# MDR1206AFI register map
Vendor: Milandr; File version: 2.0
CPU: BM-310S0, little endian
Registers are 32-bit, read-write, reset 0x0 unless marked. A register's access mark holds for its fields unless they carry their own. Offsets are from the block's base; [hi:lo] are bit positions; {n}, {i} and the like mark numbered series; 'fields as' and 'values as' point back to an identical list.

## BKP — Backup domain
Base 0x50060000
0x00 WPR — Key Register
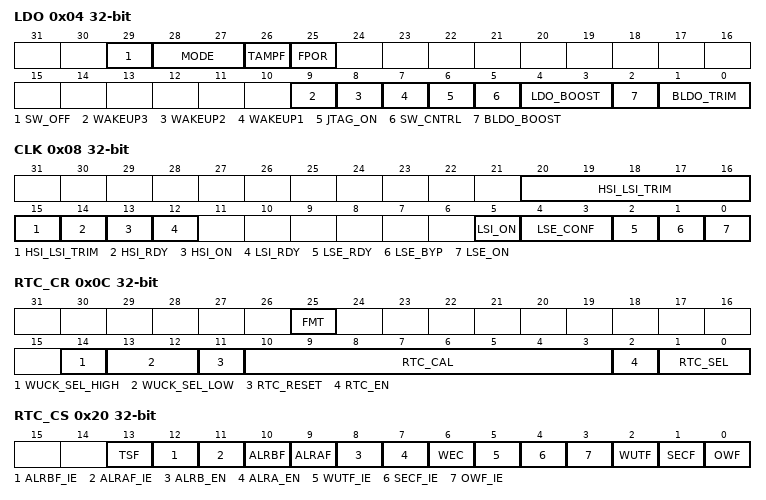
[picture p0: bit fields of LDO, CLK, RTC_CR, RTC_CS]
0x04 LDO — LDO Control Register
  [29] SW_OFF — Write "1" to switch off battery backup
  [28:27] MODE — Operating Mode
  [26] TAMPF — Signals if there was a break-in
  [25] FPOR — POR Trigger Flag
  [9] WAKEUP3 ro — WAKEUP3 state
  [8] WAKEUP2 ro — WAKEUP2 state
  [7] WAKEUP1 ro — WAKEUP1 state
  [6] JTAG_ON — Enables JTAG operation
  [5] SW_CNTRL — Enables SW control
  [4:3] LDO_BOOST — Enables Boost mode of LDO
  [2] BLDO_BOOST — Enables Boost mode of BLDO
    0=Typical value; 1=BLDO trimming is enabled
  [1:0] BLDO_TRIM — Backup domain LDO trimming
0x08 CLK — Clock Register
  [20:15] HSI_LSI_TRIM — HSI and LSI trimming value
  [14] HSI_RDY ro — Signals if HSI is ready
  [13] HSI_ON — Enables HSI
  [12] LSI_RDY ro — Signals if LSI is ready
  [5] LSI_ON — Enables LSI
  [4:3] LSE_CONF — LSE Configuration Register
    0=Default Mode; 1=Glitch filter is on; 2=Booster current is increased; 3=Booster current is increased and glitch filter is on
  [2] LSE_RDY ro — Signals if LSE is ready
  [1] LSE_BYP — Enables bypass mode of LSE
  [0] LSE_ON — Enables LSE
0x0C RTC_CR — RTC Control Register
  [25] FMT — Format
    0=24 hours; 1=AM/PM
  [14] WUCK_SEL_HIGH — Selects clocking for WDT
    0=Independent clocking from WUCK_SEL[1:0]; 1=Common clocking with the counter/calendar
  [13:12] WUCK_SEL_LOW — Selects independent clock for WDG (WUCK_SEL[1:0])
    0=BY 16; 1=BY 8; 2=BY 4; 3=BY 2
  [11] RTC_RESET — Resets RTC
  [10:3] RTC_CAL — RTC Clock Calibration
  [2] RTC_EN — Enables RTC operation
  [1:0] RTC_SEL — Selects RTC source
    0=LSI; 1=LSE; 2=HSI_RTC; 3=HSE_RTC
0x10 RTC_WUTR — WDG Counter Register
0x14 RTC_PREDIV_S — Counter/Calendar Preliminary Divisor Register
  [19:0] RTC_DIV — Counter/Calendar divisor
0x18 RTC_PRL — RTC Prescaler Register
  [19:0] RTC_PRL — RTC prescaler
0x1C RTC_ALRM — RTC Alarm Register
0x20 RTC_CS — RTC Control and Status Register
  [13] TSF — Time Stamp Flag
  [12] ALRBF_IE — ALRBF Interrupt Enable
  [11] ALRAF_IE — ALRAF Interrupt Enable
  [10] ALRBF — Event B Flag
  [9] ALRAF — Event A Flag
  [8] ALRB_EN — Enables event B (coincidence of BKP_RTC_ALRMBR and running time)
  [7] ALRA_EN — Enables event A (coincidence of BKP_RTC_ALRMAR and running time)
  [6] WEC ro — WEC description
  [5] WUTF_IE — Enables WUTF interrup
  [4] SECF_IE — Enables SECF interrup
  [3] OWF_IE — Enables OWF interrupt
  [2] WUTF — Signals if BKP_RTC_WUTR is greater than BKP_RTC_ALRM
  [1] SECF — Siganls if the values of BKP_RTC_PREDIV_S and BKP_RTC_PRL coincide
  [0] OWF — Overflow of BKP_RTC_WUT
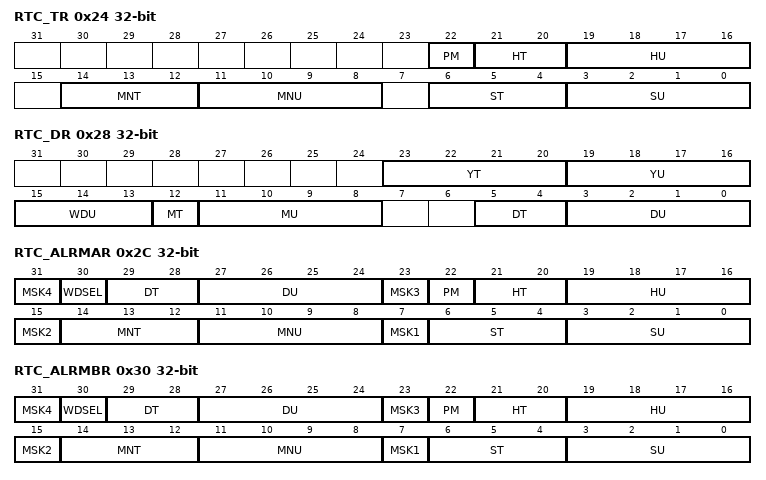
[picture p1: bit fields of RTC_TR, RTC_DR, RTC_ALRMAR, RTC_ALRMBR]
0x24 RTC_TR — Counter/Calendar Time Register (BCD format)
  [22] PM — AM/PM value
  [21:20] HT — The tens of hours (BCD format)
  [19:16] HU — The units of hours (BCD format)
  [14:12] MNT — The tens of minutes (BCD format)
  [11:8] MNU — The units of minutes (BCD format)
  [6:4] ST — The tens of seconds (BCD format)
  [3:0] SU — The units of seconds (BCD format)
0x28 RTC_DR — Counter/Calendar Data Register (BCD format)
  [23:20] YT — The tens of the years (BCD format)
  [19:16] YU — The units of the years (BCD format)
  [15:13] WDU — A weekday
    0=Not used; 1=Monday; 2=Tuesday; 3=Wednesday; 4=Thursday; 5=Friday; 6=Saturday; 7=Sunday
  [12] MT — The tens of the month (BCD format)
  [11:8] MU — The units of the month (BCD format)
  [5:4] DT — The tens of the date (BCD format)
  [3:0] DU — The units of the date (BCD format)
0x2C RTC_ALRMAR — Settings of the alarm A
  [31] MSK4 — A maks for the date
    0=Date; 1=NO_DATE
  [30] WDSEL — Day or date selection
    0=Date (DU[3:0], DT[1:0]); 1=Day of the week (DU[3:0] defines the day of the week)
  [29:28] DT — Tens of a date in BCD-format
  [27:24] DU — Units of a date in BCD-format
  [23] MSK3 — A mask for hours
    0=HOURS; 1=NO_HOURS
  [22] PM — AM/PM setting
    0=AM or 24-hour clock; 1=PM
  [21:20] HT — Tens of hours in BCD-format
  [19:16] HU — Units of hours in BCD-format
  [15] MSK2 — A mask for minutes
    0=MIN; 1=NO_MIN
  [14:12] MNT — Tens of minutes in BCD-format
  [11:8] MNU — Units of minutes in BCD-format
  [7] MSK1 — A mask for seconds
    0=SEC; 1=NO_SEC
  [6:4] ST — Tens of seconds in BCD-format
  [3:0] SU — Units of seconds in BCD-format
0x30 RTC_ALRMBR — Settings of the alarm B
  fields as RTC_ALRMAR
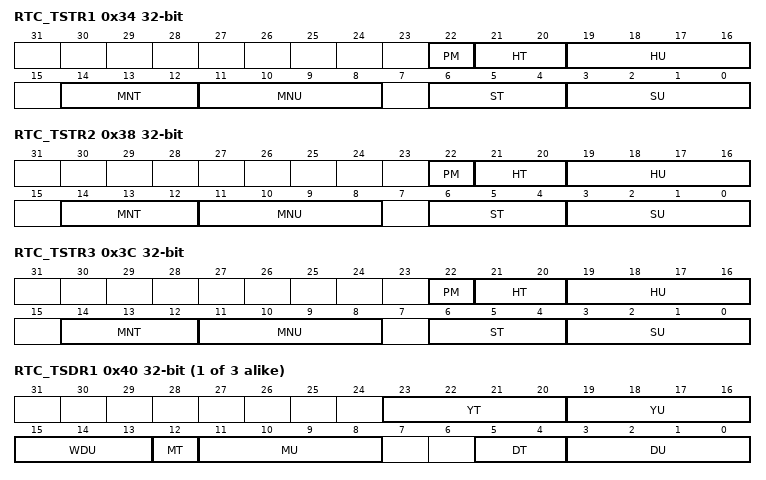
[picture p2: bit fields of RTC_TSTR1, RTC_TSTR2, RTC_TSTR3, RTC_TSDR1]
0x34 RTC_TSTR1 ro — Time of an external intrusion
  fields as RTC_TR
0x38 RTC_TSTR2 ro — Time of an xternal intrusion
  fields as RTC_TR
0x3C RTC_TSTR3 ro — Time of an external Intrusion
  fields as RTC_TR
{0x3C+4i} RTC_TSDR{i} ro (i=1..3) — Data of an external Intrusion
  fields as RTC_DR
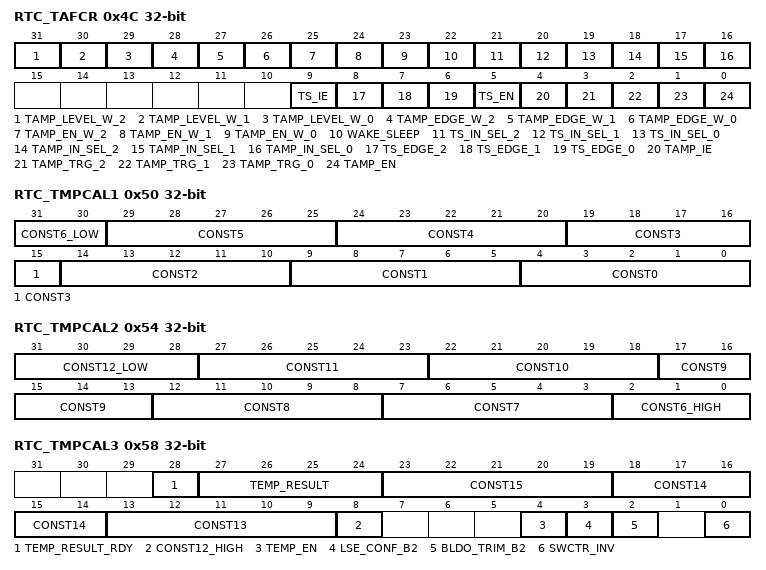
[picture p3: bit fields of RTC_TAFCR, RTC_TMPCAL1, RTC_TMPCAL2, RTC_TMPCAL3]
0x4C RTC_TAFCR — Control Register for an Intrusion Fixation
  [31] TAMP_LEVEL_W_2 — The level fixation for WAKEUP3
    0=FIX_ON (Fixes the level with pulse width greater than 2 cycles of RTC_CLOCK); 1=FIX_OFF
  [30] TAMP_LEVEL_W_1 — The level fixation for WAKEUP2
    values as TAMP_LEVEL_W_2
  [29] TAMP_LEVEL_W_0 — The level fixation for WAKEUP1
    values as TAMP_LEVEL_W_2
  [28] TAMP_EDGE_W_2 — A rising edge fixation for WAKEUP3
    0=FIX_ON; 1=FIX_OFF (An impulse with the width less than 2 cycles of RTC_CLOCK is not fixed. The width greater than 2 cycles of RTC_CLOCK may be fixed depending on TAMP_LEVEL_W)
  [27] TAMP_EDGE_W_1 — A rising edge fixation for WAKEUP2
    values as TAMP_EDGE_W_2
  [26] TAMP_EDGE_W_0 — A rising edge fixation for WAKEUP1
    values as TAMP_EDGE_W_2
  [25] TAMP_EN_W_2 — Individual enabling of TAMPER detection for WAKEUP3 when TAMP_EN = 0
  [24] TAMP_EN_W_1 — Individual enabling of TAMPER detection for WAKEUP2 when TAMP_EN = 0
  [23] TAMP_EN_W_0 — Individual enabling of TAMPER detection for WAKEUP1 when TAMP_EN = 0
  [22] WAKE_SLEEP — Selects switching on or off of the SW when WUTF=1
    0=SW_OFF; 1=SW_ON
  [21] TS_IN_SEL_2 — Signals if an external event for WAKEUP3 has been detected by TIMESTAMP
  [20] TS_IN_SEL_1 — Signals if an external event for WAKEUP2 has been detected by TIMESTAMP
  [19] TS_IN_SEL_0 — Signals if an external event for WAKEUP1 has been detected by TIMESTAMP
  [18] TAMP_IN_SEL_2 — Signals if an external event for WAKEUP3 has been detected by TAMPER
  [17] TAMP_IN_SEL_1 — Signals if an external event for WAKEUP2 has been detected by TAMPER
  [16] TAMP_IN_SEL_0 — Signals if an external event for WAKEUP1 has been detected by TAMPER
  [9] TS_IE — Enables interrupt when TIMESTAMP is fixed
  [8] TS_EDGE_2 — Sets the operating edge for TIMESTAMP at WAKEUP3
    0=RE_HIGHLEV; 1=FE_LOWLEV
  [7] TS_EDGE_1 — Sets the operating edge for TIMESTAMP at WAKEUP2
    0=RE_HIGHLEV; 1=FE_LOWLEV
  [6] TS_EDGE_0 — Sets the operating edge for TIMESTAMP at WAKEUP1
    0=RE_HIGHLEV; 1=FE_LOWLEV
  [5] TS_EN — Enables time storing when TIMESTAMP is fixed
  [4] TAMP_IE — Enables Tamper interrupt
  [3] TAMP_TRG_2 — Active trigger of Tamper event for WAKEUP3
    0=POSED_HIGHLEV; 1=NEGED_LOWLEV
  [2] TAMP_TRG_1 — Active trigger of Tamper event for WAKEUP2
    0=POSED_HIGHLEV; 1=NEGED_LOWLEV
  [1] TAMP_TRG_0 — Active trigger of Tamper event for WAKEUP1
    0=POSED_HIGHLEV; 1=NEGED_LOWLEV
  [0] TAMP_EN — Detection of Tamper event for WAKEUP1 - WAKEUP3 inputs
0x50 RTC_TMPCAL1 — Calibration and Thermocompensation Unit Control Register 1
  [31:30] CONST6_LOW — Low-order bits of the calibration constant for code 6 of the thermosensor
  [5n+4:5n] CONST{n} (n=0..5) — Calibration constant for code {n} of the thermosensor
0x54 RTC_TMPCAL2 — Calibration and Thermocompensation Unit Control Register 2
  [31:28] CONST12_LOW — Low-order bits of the calibration constant for code 12 of the thermosensor
  [5n-28:5n-32] CONST{n} (n=7..11) — Calibration constant for code {n} of the thermosensor
  [2:0] CONST6_HIGH — High-order bits of the calibration constant for code 6 of the thermosensor
0x58 RTC_TMPCAL3 — Calibration and Thermocompensation Unit Control Register 3
  [28] TEMP_RESULT_RDY ro — Signals readiness of TEMP_RESULT[3:0]
    0=INVALID; 1=VALID
  [27:24] TEMP_RESULT ro — Thermosensor result
  [23:19] CONST15 — Calibration constant for code 15 of the thermosensor
  [18:14] CONST14 — Calibration constant for code 14 of the thermosensor
  [13:9] CONST13 — Calibration constant for code 13 of the thermosensor
  [8] CONST12_HIGH — High-order bit of the calibration constant for code 12 of the thermosensor
  [4] TEMP_EN — Enables the thermosensor
  [3] LSE_CONF_B2 — always write as zero
  [2] BLDO_TRIM_B2 — always write as zero
  [0] SWCTR_INV — Inversion of control logic for the SW (open drain)
    0=HZ_into_0 (when SW_PWR = 1); 1=0_into_HZ (when SW_PWR = 1)
